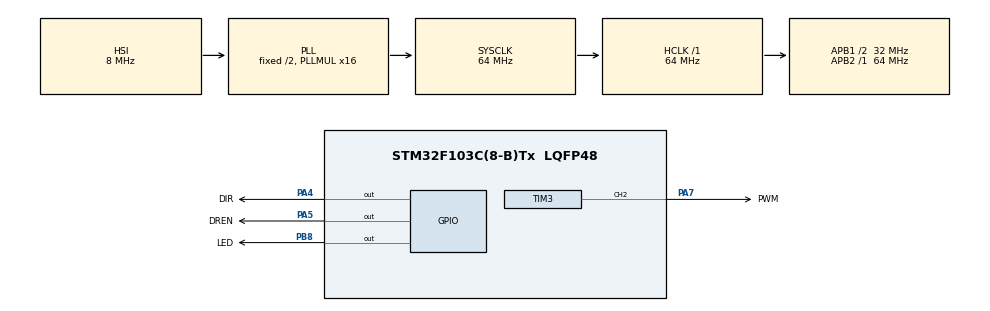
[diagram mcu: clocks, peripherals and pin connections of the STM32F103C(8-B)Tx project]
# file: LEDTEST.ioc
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Mcu.Family=STM32F1
Mcu.Name=STM32F103C(8-B)Tx
Mcu.Package=LQFP48
NVIC.PriorityGroup=NVIC_PRIORITYGROUP_4
NVIC.TIM3_IRQn=true\:0\:0\:false\:false\:true\:true\:true
PA4.GPIO_Label=DIR
PA4.Signal=GPIO_Output
PA5.GPIO_Label=DREN
PA5.Signal=GPIO_Output
PA7.GPIO_Label=PWM
PA7.Signal=S_TIM3_CH2
PB8.GPIO_Label=LED
PB8.Signal=GPIO_Output
PD0-OSC_IN.Mode=HSE-External-Oscillator
PD0-OSC_IN.Signal=RCC_OSC_IN
PD1-OSC_OUT.Mode=HSE-External-Oscillator
PD1-OSC_OUT.Signal=RCC_OSC_OUT
ProjectManager.HeapSize=0x200
ProjectManager.StackSize=0x400
ProjectManager.TargetToolchain=STM32CubeIDE
RCC.AHBFreq_Value=64000000
RCC.APB1CLKDivider=RCC_HCLK_DIV2
RCC.APB1Freq_Value=32000000
RCC.APB1TimFreq_Value=64000000
RCC.APB2Freq_Value=64000000
RCC.APB2TimFreq_Value=64000000
RCC.HCLKFreq_Value=64000000
RCC.PLLMUL=RCC_PLL_MUL16
RCC.SYSCLKFreq_VALUE=64000000
RCC.SYSCLKSource=RCC_SYSCLKSOURCE_PLLCLK
RCC.USBFreq_Value=64000000
SH.S_TIM3_CH2.0=TIM3_CH2,PWM Generation2 CH2
TIM3.Channel-PWM\ Generation2\ CH2=TIM_CHANNEL_2
TIM3.Period=1000-1
TIM3.Prescaler=40-1
TIM3.Pulse-PWM\ Generation2\ CH2=500-1
VP_SYS_VS_ND.Mode=No_Debug
board=custom

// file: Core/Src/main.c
/* USER CODE BEGIN Header */
/**
  ******************************************************************************
  * @file           : main.c
  * @brief          : Main program body
  ******************************************************************************
  * @attention
  *
  * <h2><center>&copy; Copyright (c) 2021 STMicroelectronics.
  * All rights reserved.</center></h2>
  *
  * This software component is licensed by ST under BSD 3-Clause license,
  * the "License"; You may not use this file except in compliance with the
  * License. You may obtain a copy of the License at:
  *                        opensource.org/licenses/BSD-3-Clause
  *
  ******************************************************************************
  */
/* USER CODE END Header */
#include "main.h"
#include "tim.h"

TIM_HandleTypeDef htim3;

void SystemClock_Config(void);
static void MX_GPIO_Init(void);
static void MX_TIM3_Init(void);

int main(void)
{

  /* MCU Configuration--------------------------------------------------------*/

  /* Reset of all peripherals, Initializes the Flash interface and the Systick. */
  HAL_Init();

  /* Configure the system clock */
  SystemClock_Config();

  /* Initialize all configured peripherals */
  MX_GPIO_Init();
  MX_TIM3_Init();
  /* USER CODE BEGIN 2 */

  HAL_TIM_Base_Start_IT(&htim3);
  HAL_TIM_PWM_Start(&htim3, TIM_CHANNEL_2);
  /* USER CODE END 2 */

  /* Infinite loop */
  while (1)
  {

  }
}

void SystemClock_Config(void)
{
  RCC_OscInitTypeDef RCC_OscInitStruct = {0};
  RCC_ClkInitTypeDef RCC_ClkInitStruct = {0};

  /** Initializes the RCC Oscillators according to the specified parameters
  * in the RCC_OscInitTypeDef structure.
  */
  RCC_OscInitStruct.OscillatorType = RCC_OSCILLATORTYPE_HSI;
  RCC_OscInitStruct.HSIState = RCC_HSI_ON;
  RCC_OscInitStruct.HSICalibrationValue = RCC_HSICALIBRATION_DEFAULT;
  RCC_OscInitStruct.PLL.PLLState = RCC_PLL_ON;
  RCC_OscInitStruct.PLL.PLLSource = RCC_PLLSOURCE_HSI_DIV2;
  RCC_OscInitStruct.PLL.PLLMUL = RCC_PLL_MUL16;
  if (HAL_RCC_OscConfig(&RCC_OscInitStruct) != HAL_OK)
  {
    Error_Handler();
  }
  /** Initializes the CPU, AHB and APB buses clocks
  */
  RCC_ClkInitStruct.ClockType = RCC_CLOCKTYPE_HCLK|RCC_CLOCKTYPE_SYSCLK
                              |RCC_CLOCKTYPE_PCLK1|RCC_CLOCKTYPE_PCLK2;
  RCC_ClkInitStruct.SYSCLKSource = RCC_SYSCLKSOURCE_PLLCLK;
  RCC_ClkInitStruct.AHBCLKDivider = RCC_SYSCLK_DIV1;
  RCC_ClkInitStruct.APB1CLKDivider = RCC_HCLK_DIV2;
  RCC_ClkInitStruct.APB2CLKDivider = RCC_HCLK_DIV1;

  if (HAL_RCC_ClockConfig(&RCC_ClkInitStruct, FLASH_LATENCY_2) != HAL_OK)
  {
    Error_Handler();
  }
}

static void MX_TIM3_Init(void)
{

  TIM_MasterConfigTypeDef sMasterConfig = {0};
  TIM_OC_InitTypeDef sConfigOC = {0};

  htim3.Instance = TIM3;
  htim3.Init.Prescaler = 40-1;
  htim3.Init.CounterMode = TIM_COUNTERMODE_UP;
  htim3.Init.Period = 1000-1;
  htim3.Init.ClockDivision = TIM_CLOCKDIVISION_DIV1;
  htim3.Init.AutoReloadPreload = TIM_AUTORELOAD_PRELOAD_DISABLE;
  if (HAL_TIM_PWM_Init(&htim3) != HAL_OK)
  {
    Error_Handler();
  }
  sMasterConfig.MasterOutputTrigger = TIM_TRGO_RESET;
  sMasterConfig.MasterSlaveMode = TIM_MASTERSLAVEMODE_DISABLE;
  if (HAL_TIMEx_MasterConfigSynchronization(&htim3, &sMasterConfig) != HAL_OK)
  {
    Error_Handler();
  }
  sConfigOC.OCMode = TIM_OCMODE_PWM1;
  sConfigOC.Pulse = 500-1;
  sConfigOC.OCPolarity = TIM_OCPOLARITY_HIGH;
  sConfigOC.OCFastMode = TIM_OCFAST_DISABLE;
  if (HAL_TIM_PWM_ConfigChannel(&htim3, &sConfigOC, TIM_CHANNEL_2) != HAL_OK)
  {
    Error_Handler();
  }
  HAL_TIM_MspPostInit(&htim3);

}

static void MX_GPIO_Init(void)
{
  GPIO_InitTypeDef GPIO_InitStruct = {0};

  /* GPIO Ports Clock Enable */
  __HAL_RCC_GPIOD_CLK_ENABLE();
  __HAL_RCC_GPIOA_CLK_ENABLE();
  __HAL_RCC_GPIOB_CLK_ENABLE();

  /*Configure GPIO pin Output Level */
  HAL_GPIO_WritePin(GPIOA, DIR_Pin|DREN_Pin, GPIO_PIN_RESET);

  /*Configure GPIO pin Output Level */
  HAL_GPIO_WritePin(LED_GPIO_Port, LED_Pin, GPIO_PIN_RESET);

  /*Configure GPIO pins : DIR_Pin DREN_Pin */
  GPIO_InitStruct.Pin = DIR_Pin|DREN_Pin;
  GPIO_InitStruct.Mode = GPIO_MODE_OUTPUT_PP;
  GPIO_InitStruct.Pull = GPIO_NOPULL;
  GPIO_InitStruct.Speed = GPIO_SPEED_FREQ_LOW;
  HAL_GPIO_Init(GPIOA, &GPIO_InitStruct);

  /*Configure GPIO pin : LED_Pin */
  GPIO_InitStruct.Pin = LED_Pin;
  GPIO_InitStruct.Mode = GPIO_MODE_OUTPUT_PP;
  GPIO_InitStruct.Pull = GPIO_NOPULL;
  GPIO_InitStruct.Speed = GPIO_SPEED_FREQ_LOW;
  HAL_GPIO_Init(LED_GPIO_Port, &GPIO_InitStruct);

}

void Error_Handler(void)
{
  __disable_irq();
  while (1)
  {
  }
}

/************************ (C) COPYRIGHT STMicroelectronics *****END OF FILE****/
